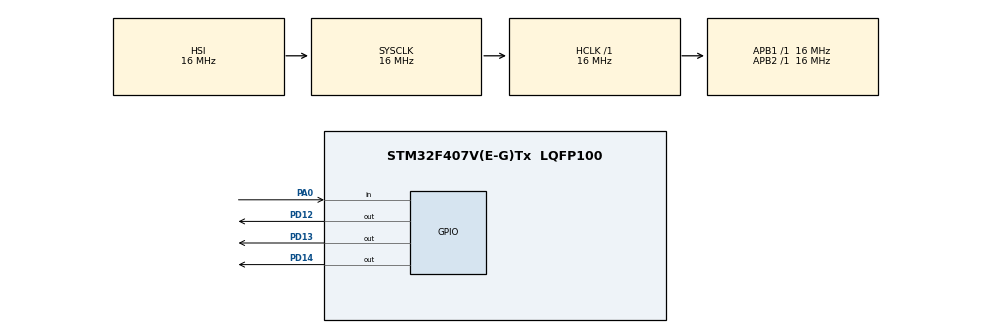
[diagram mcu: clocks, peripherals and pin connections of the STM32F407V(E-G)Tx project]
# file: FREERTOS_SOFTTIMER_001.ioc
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FREERTOS.Tasks01=led1Task,0,128,StartLed1Task,Default,NULL,Dynamic,NULL,NULL;led2Task,0,128,StartLed2Task02,Default,NULL,Dynamic,NULL,NULL
FREERTOS.Timers01=PTCallback,PTCallback01,osTimerPeriodic,Default,NULL,Dynamic,NULL;OSTCallback,OSTCallback1,osTimerOnce,Default,NULL,Dynamic,NULL
FREERTOS.configTIMER_TASK_PRIORITY=6
FREERTOS.configUSE_NEWLIB_REENTRANT=1
FREERTOS.configUSE_TIMERS=1
Mcu.Family=STM32F4
Mcu.Name=STM32F407V(E-G)Tx
Mcu.Package=LQFP100
NVIC.PriorityGroup=NVIC_PRIORITYGROUP_4
NVIC.TIM6_DAC_IRQn=true\:15\:0\:false\:false\:true\:false\:false\:true\:true
NVIC.TimeBase=TIM6_DAC_IRQn
NVIC.TimeBaseIP=TIM6
PA0-WKUP.Signal=GPIO_Input
PA13.Mode=Serial_Wire
PA13.Signal=SYS_JTMS-SWDIO
PA14.Mode=Serial_Wire
PA14.Signal=SYS_JTCK-SWCLK
PD12.Signal=GPIO_Output
PD13.Signal=GPIO_Output
PD14.Signal=GPIO_Output
PH0-OSC_IN.Mode=HSE-External-Oscillator
PH0-OSC_IN.Signal=RCC_OSC_IN
PH1-OSC_OUT.Mode=HSE-External-Oscillator
PH1-OSC_OUT.Signal=RCC_OSC_OUT
ProjectManager.HeapSize=0x200
ProjectManager.StackSize=0x400
ProjectManager.TargetToolchain=STM32CubeIDE
RCC.AHBFreq_Value=16000000
RCC.APB1Freq_Value=16000000
RCC.APB2Freq_Value=16000000
RCC.CortexFreq_Value=16000000
RCC.HSE_VALUE=25000000
RCC.HSI_VALUE=16000000
RCC.LSE_VALUE=32768
RCC.SYSCLKFreq_VALUE=16000000
RCC.VCOOutputFreq_Value=192000000
VP_FREERTOS_VS_CMSIS_V1.Mode=CMSIS_V1
VP_SYS_VS_tim6.Mode=TIM6
board=custom

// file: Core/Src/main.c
/* USER CODE BEGIN Header */
/**
  ******************************************************************************
  * @file           : main.c
  * @brief          : Main program body
  ******************************************************************************
  * @attention
  *
  * Copyright (c) 2024 STMicroelectronics.
  * All rights reserved.
  *
  * This software is licensed under terms that can be found in the LICENSE file
  * in the root directory of this software component.
  * If no LICENSE file comes with this software, it is provided AS-IS.
  *
  ******************************************************************************
  */
/* USER CODE END Header */
#include "main.h"
// #include "cmsis_os.h"

#include "FreeRTOS.h"
#include "task.h"
#include "timers.h"
#include "queue.h"
#include "semphr.h"
#include "event_groups.h"

//osThreadId led1TaskHandle;
//osThreadId led2TaskHandle;
//osTimerId PTCallbackHandle;
//osTimerId OSTCallbackHandle;

void SystemClock_Config(void);
static void MX_GPIO_Init(void);
//void StartLed1Task(void const * argument);
//void StartLed2Task02(void const * argument);
//void PTCallback01(void const * argument);
//void OSTCallback1(void const * argument);

void led1Task(void* argument);
void led2Task(void* argument);

/* USER CODE BEGIN 0 */

void TimerCallback(xTimerHandle xTimer);
void someFunction();

xTimerHandle PTHandle;
xTimerHandle OTHandle;

xTaskHandle led1Handle;
xTaskHandle led2Handle;

/* definition and creation of OSTCallback */
// osTimerDef(OSTCallback, OSTCallback1);
// OSTCallbackHandle = osTimerCreate(osTimer(OSTCallback), osTimerOnce, NULL);
void someFunction() {
    // Create and assign the timers
    PTHandle = xTimerCreate("timer1", pdMS_TO_TICKS(1000), pdTRUE, (void *)1, TimerCallback);
    OTHandle = xTimerCreate("timer2", pdMS_TO_TICKS(4000), pdFALSE, (void *)2, TimerCallback);

    // Other code...
}

/* USER CODE END 0 */

int main(void)
{

  /* MCU Configuration--------------------------------------------------------*/

  /* Reset of all peripherals, Initializes the Flash interface and the Systick. */
  HAL_Init();

  /* Configure the system clock */
  SystemClock_Config();

  /* Initialize all configured peripherals */
  MX_GPIO_Init();

  /* Create the timer(s) */
  /* definition and creation of PTCallback */
  // osTimerDef(PTCallback, PTCallback01);
  // PTCallbackHandle = osTimerCreate(osTimer(PTCallback), osTimerPeriodic, NULL);

  /* Create the thread(s) */
  /* definition and creation of led1Task */
  //osThreadDef(led1Task, StartLed1Task, osPriorityNormal, 0, 128);
  // led1TaskHandle = osThreadCreate(osThread(led1Task), NULL);

  xTaskCreate(led1Task, "led1", 128, NULL, 1, &led1Handle);
  xTaskCreate(led2Task, "led2", 128, NULL, 1, &led2Handle);

  someFunction();

  /* definition and creation of led2Task */
  // osThreadDef(led2Task, StartLed2Task02, osPriorityNormal, 0, 128);
  // led2TaskHandle = osThreadCreate(osThread(led2Task), NULL);

  /* Start scheduler */
  // osKernelStart();
  vTaskStartScheduler();
  /* We should never get here as control is now taken by the scheduler */

  /* Infinite loop */
  while (1)
  {

  }
}

void SystemClock_Config(void)
{
  RCC_OscInitTypeDef RCC_OscInitStruct = {0};
  RCC_ClkInitTypeDef RCC_ClkInitStruct = {0};

  /** Configure the main internal regulator output voltage
  */
  __HAL_RCC_PWR_CLK_ENABLE();
  __HAL_PWR_VOLTAGESCALING_CONFIG(PWR_REGULATOR_VOLTAGE_SCALE1);

  /** Initializes the RCC Oscillators according to the specified parameters
  * in the RCC_OscInitTypeDef structure.
  */
  RCC_OscInitStruct.OscillatorType = RCC_OSCILLATORTYPE_HSI;
  RCC_OscInitStruct.HSIState = RCC_HSI_ON;
  RCC_OscInitStruct.HSICalibrationValue = RCC_HSICALIBRATION_DEFAULT;
  RCC_OscInitStruct.PLL.PLLState = RCC_PLL_NONE;
  if (HAL_RCC_OscConfig(&RCC_OscInitStruct) != HAL_OK)
  {
    Error_Handler();
  }

  /** Initializes the CPU, AHB and APB buses clocks
  */
  RCC_ClkInitStruct.ClockType = RCC_CLOCKTYPE_HCLK|RCC_CLOCKTYPE_SYSCLK
                              |RCC_CLOCKTYPE_PCLK1|RCC_CLOCKTYPE_PCLK2;
  RCC_ClkInitStruct.SYSCLKSource = RCC_SYSCLKSOURCE_HSI;
  RCC_ClkInitStruct.AHBCLKDivider = RCC_SYSCLK_DIV1;
  RCC_ClkInitStruct.APB1CLKDivider = RCC_HCLK_DIV1;
  RCC_ClkInitStruct.APB2CLKDivider = RCC_HCLK_DIV1;

  if (HAL_RCC_ClockConfig(&RCC_ClkInitStruct, FLASH_LATENCY_0) != HAL_OK)
  {
    Error_Handler();
  }
}

static void MX_GPIO_Init(void)
{
  GPIO_InitTypeDef GPIO_InitStruct = {0};

  /* GPIO Ports Clock Enable */
  __HAL_RCC_GPIOH_CLK_ENABLE();
  __HAL_RCC_GPIOA_CLK_ENABLE();
  __HAL_RCC_GPIOD_CLK_ENABLE();

  /*Configure GPIO pin Output Level */
  HAL_GPIO_WritePin(GPIOD, GPIO_PIN_12|GPIO_PIN_13|GPIO_PIN_14, GPIO_PIN_RESET);

  /*Configure GPIO pin : PA0 */
  GPIO_InitStruct.Pin = GPIO_PIN_0;
  GPIO_InitStruct.Mode = GPIO_MODE_INPUT;
  GPIO_InitStruct.Pull = GPIO_NOPULL;
  HAL_GPIO_Init(GPIOA, &GPIO_InitStruct);

  /*Configure GPIO pins : PD12 PD13 PD14 */
  GPIO_InitStruct.Pin = GPIO_PIN_12|GPIO_PIN_13|GPIO_PIN_14;
  GPIO_InitStruct.Mode = GPIO_MODE_OUTPUT_PP;
  GPIO_InitStruct.Pull = GPIO_NOPULL;
  GPIO_InitStruct.Speed = GPIO_SPEED_FREQ_LOW;
  HAL_GPIO_Init(GPIOD, &GPIO_InitStruct);

}

//void StartLed1Task(void const * argument)
//{
//  /* USER CODE BEGIN 5 */
//	osTimerStart(PTCallbackHandle, 1000);
//
//  /* Infinite loop */
//  for(;;)
//  {
//	  HAL_GPIO_TogglePin(GPIOD,GPIO_PIN_12);
//	  osDelay(2000);
//  }
//  /* USER CODE END 5 */
//}

void led1Task(void* argument)
{
	xTimerStart(PTHandle,0);

	while(1)
	{
		HAL_GPIO_TogglePin(GPIOD,GPIO_PIN_12);
		vTaskDelay(2000);
	}

}

void led2Task(void* argument)
{

	while(1)
	{
		if(HAL_GPIO_ReadPin(GPIOA,GPIO_PIN_0) == 1)
		{
			while(HAL_GPIO_ReadPin(GPIOA,GPIO_PIN_0));
			xTimerStart(OTHandle,0);
		}
	}

}

//void StartLed2Task02(void const * argument)
//{
//  /* USER CODE BEGIN StartLed2Task02 */
//  /* Infinite loop */
//  for(;;)
//  {
//	  if(HAL_GPIO_ReadPin(GPIOA,GPIO_PIN_0) == 1)
//	  {
//		  while(HAL_GPIO_ReadPin(GPIOA,GPIO_PIN_0));
//		  osTimerStart(OSTCallbackHandle, 4000);
//
//	  }
//
//    osDelay(20);
//  }
//  /* USER CODE END StartLed2Task02 */
//}

/* PTCallback01 function */
//void PTCallback01(void const * argument)
//{
//  /* USER CODE BEGIN PTCallback01 */
//
//	HAL_GPIO_TogglePin(GPIOD,GPIO_PIN_13);
//
//  /* USER CODE END PTCallback01 */
//}
//
///* OSTCallback1 function */
//void OSTCallback1(void const * argument)
//{
//  /* USER CODE BEGIN OSTCallback1 */
//
//	HAL_GPIO_TogglePin(GPIOD,GPIO_PIN_14);
//
//  /* USER CODE END OSTCallback1 */
//}

void TimerCallback(xTimerHandle xTimer)
{
	if(xTimer == PTHandle)
	{
		HAL_GPIO_TogglePin(GPIOD,GPIO_PIN_13);
	}
	else if(xTimer == OTHandle)
	{
		HAL_GPIO_TogglePin(GPIOD,GPIO_PIN_14);
	}

}

void HAL_TIM_PeriodElapsedCallback(TIM_HandleTypeDef *htim)
{
  if (htim->Instance == TIM6) {
    HAL_IncTick();
  }
}

void Error_Handler(void)
{
  __disable_irq();
  while (1)
  {
  }
}
